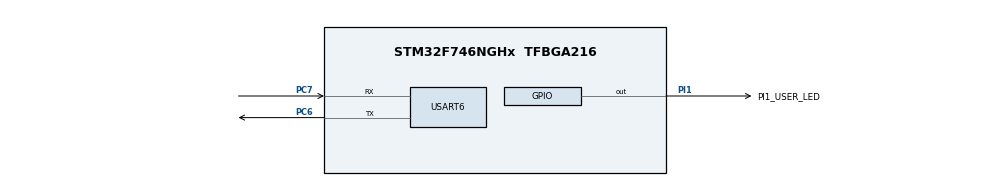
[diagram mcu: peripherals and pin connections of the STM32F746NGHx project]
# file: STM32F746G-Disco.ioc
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Mcu.Family=STM32F7
PC6.Signal=USART6_TX
ProjectManager.StackSize=0x400
ProjectManager.TargetToolchain=STM32CubeIDE
PC6.Mode=Asynchronous
PC7.Signal=USART6_RX
USART6.VirtualMode-Asynchronous=VM_ASYNC
RCC.USBFreq_Value=96000000
RCC.LSE_VALUE=32768
RCC.HSE_VALUE=25000000
board=custom
RCC.VCOOutputFreq_Value=192000000
PI1.Signal=GPIO_Output
Mcu.Name=STM32F746NGHx
Mcu.Package=TFBGA216
ProjectManager.HeapSize=0x200
RCC.HSI_VALUE=16000000
NVIC.PriorityGroup=NVIC_PRIORITYGROUP_4
PC7.Mode=Asynchronous
PI1.GPIO_Label=PI1_USER_LED

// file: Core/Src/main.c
/* USER CODE BEGIN Header */
/**
  ******************************************************************************
  * @file           : main.c
  * @brief          : Main program body
  ******************************************************************************
  * @attention
  *
  * <h2><center>&copy; Copyright (c) 2021 STMicroelectronics.
  * All rights reserved.</center></h2>
  *
  * This software component is licensed by ST under BSD 3-Clause license,
  * the "License"; You may not use this file except in compliance with the
  * License. You may obtain a copy of the License at:
  *                        opensource.org/licenses/BSD-3-Clause
  *
  ******************************************************************************
  */
/* USER CODE END Header */
#include "main.h"

UART_HandleTypeDef huart6;

void SystemClock_Config(void);
static void MX_GPIO_Init(void);
static void MX_USART6_UART_Init(void);

/* USER CODE BEGIN 0 */

void Serial6Print(char *ptr)
{
	while(*ptr != 0x00)
	{
	  while(!__HAL_UART_GET_FLAG(&huart6, UART_FLAG_TC));       // previous transmit complete?
	  HAL_UART_Transmit(&huart6,(uint8_t *)ptr++,1,10);
	}
}

void Serial6PutChar(char ch)
{
  char out[2];

  out[0] = ch;
  out[1] = 0x00;
  while(!__HAL_UART_GET_FLAG(&huart6, UART_FLAG_TC));       // previous transmit complete?
	HAL_UART_Transmit(&huart6,(uint8_t *)out,1,10);
}

void Serial6Println(char *ptr)
{
	if(*ptr != 0x00)
	{
	  Serial6Print(ptr);
	  Serial6Print("\r\n");
	}
}

/* USER CODE END 0 */

int main(void)
{

  /* MCU Configuration--------------------------------------------------------*/

  /* Reset of all peripherals, Initializes the Flash interface and the Systick. */
  HAL_Init();

  /* Configure the system clock */
  SystemClock_Config();

  /* Initialize all configured peripherals */
  MX_GPIO_Init();
  MX_USART6_UART_Init();
  /* USER CODE BEGIN 2 */
  Serial6Println("AbbeyDog Power-up");
  /* USER CODE END 2 */

  /* Infinite loop */
  /* USER CODE BEGIN WHILE */
  while (1)
  {
	  HAL_GPIO_TogglePin(PI1_USER_LED_GPIO_Port,PI1_USER_LED_Pin);
	  Serial6Print(".");
	  HAL_Delay(500);
    /* USER CODE END WHILE */

  }
}

void SystemClock_Config(void)
{
  RCC_OscInitTypeDef RCC_OscInitStruct = {0};
  RCC_ClkInitTypeDef RCC_ClkInitStruct = {0};
  RCC_PeriphCLKInitTypeDef PeriphClkInitStruct = {0};

  /** Configure the main internal regulator output voltage
  */
  __HAL_RCC_PWR_CLK_ENABLE();
  __HAL_PWR_VOLTAGESCALING_CONFIG(PWR_REGULATOR_VOLTAGE_SCALE3);
  /** Initializes the RCC Oscillators according to the specified parameters
  * in the RCC_OscInitTypeDef structure.
  */
  RCC_OscInitStruct.OscillatorType = RCC_OSCILLATORTYPE_HSI;
  RCC_OscInitStruct.HSIState = RCC_HSI_ON;
  RCC_OscInitStruct.HSICalibrationValue = RCC_HSICALIBRATION_DEFAULT;
  RCC_OscInitStruct.PLL.PLLState = RCC_PLL_NONE;
  if (HAL_RCC_OscConfig(&RCC_OscInitStruct) != HAL_OK)
  {
    Error_Handler();
  }
  /** Initializes the CPU, AHB and APB buses clocks
  */
  RCC_ClkInitStruct.ClockType = RCC_CLOCKTYPE_HCLK|RCC_CLOCKTYPE_SYSCLK
                              |RCC_CLOCKTYPE_PCLK1|RCC_CLOCKTYPE_PCLK2;
  RCC_ClkInitStruct.SYSCLKSource = RCC_SYSCLKSOURCE_HSI;
  RCC_ClkInitStruct.AHBCLKDivider = RCC_SYSCLK_DIV1;
  RCC_ClkInitStruct.APB1CLKDivider = RCC_HCLK_DIV1;
  RCC_ClkInitStruct.APB2CLKDivider = RCC_HCLK_DIV1;

  if (HAL_RCC_ClockConfig(&RCC_ClkInitStruct, FLASH_LATENCY_0) != HAL_OK)
  {
    Error_Handler();
  }
  PeriphClkInitStruct.PeriphClockSelection = RCC_PERIPHCLK_USART6;
  PeriphClkInitStruct.Usart6ClockSelection = RCC_USART6CLKSOURCE_PCLK2;
  if (HAL_RCCEx_PeriphCLKConfig(&PeriphClkInitStruct) != HAL_OK)
  {
    Error_Handler();
  }
}

static void MX_USART6_UART_Init(void)
{

  huart6.Instance = USART6;
  huart6.Init.BaudRate = 115200;
  huart6.Init.WordLength = UART_WORDLENGTH_8B;
  huart6.Init.StopBits = UART_STOPBITS_1;
  huart6.Init.Parity = UART_PARITY_NONE;
  huart6.Init.Mode = UART_MODE_TX_RX;
  huart6.Init.HwFlowCtl = UART_HWCONTROL_NONE;
  huart6.Init.OverSampling = UART_OVERSAMPLING_16;
  huart6.Init.OneBitSampling = UART_ONE_BIT_SAMPLE_DISABLE;
  huart6.AdvancedInit.AdvFeatureInit = UART_ADVFEATURE_NO_INIT;
  if (HAL_UART_Init(&huart6) != HAL_OK)
  {
    Error_Handler();
  }

}

static void MX_GPIO_Init(void)
{
  GPIO_InitTypeDef GPIO_InitStruct = {0};

  /* GPIO Ports Clock Enable */
  __HAL_RCC_GPIOI_CLK_ENABLE();
  __HAL_RCC_GPIOC_CLK_ENABLE();

  /*Configure GPIO pin Output Level */
  HAL_GPIO_WritePin(PI1_USER_LED_GPIO_Port, PI1_USER_LED_Pin, GPIO_PIN_RESET);

  /*Configure GPIO pin : PI1_USER_LED_Pin */
  GPIO_InitStruct.Pin = PI1_USER_LED_Pin;
  GPIO_InitStruct.Mode = GPIO_MODE_OUTPUT_PP;
  GPIO_InitStruct.Pull = GPIO_NOPULL;
  GPIO_InitStruct.Speed = GPIO_SPEED_FREQ_LOW;
  HAL_GPIO_Init(PI1_USER_LED_GPIO_Port, &GPIO_InitStruct);

}

void Error_Handler(void)
{
  __disable_irq();
  while (1)
  {
  }
}

/************************ (C) COPYRIGHT STMicroelectronics *****END OF FILE****/
